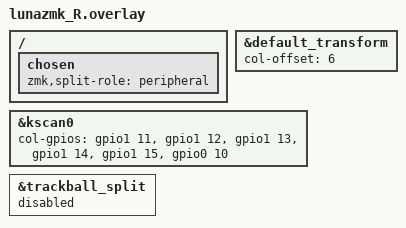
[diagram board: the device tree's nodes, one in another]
#include "lunazmk.dtsi"

/{
		chosen{
			zmk,split-role="peripheral";
		};
};

&default_transform {
    col-offset = <6>;
};

&kscan0 {
    col-gpios = <&gpio1 11 GPIO_ACTIVE_HIGH>, // D6
                <&gpio1 12 GPIO_ACTIVE_HIGH>, // D7
                <&gpio1 13 GPIO_ACTIVE_HIGH>, // D8
                <&gpio1 14 GPIO_ACTIVE_HIGH>, // D9
                <&gpio1 15 GPIO_ACTIVE_HIGH>, // D10
                <&gpio0 10 GPIO_ACTIVE_HIGH>  // NFCピン / 別のGPIO
                ;
};


&trackball_split {
    status = "disabled";
};

/*
&trackball_input_listener_0 {
    status = "disabled";
};
*/
/*
&trackball_input_listener_1 {
    status = "disabled";
};
*/
